# USB0_VBP2APB_WRAP_CONTROLLER_VBP_CORE_ADDR_MAP register map
Vendor: Texas Instruments
Registers are 32-bit, access per field, reset 0x0 unless marked. A register's access mark holds for its fields unless they carry their own. Offsets are as the file gives them; [hi:lo] are bit positions.

## USB0_VBP2APB_WRAP_CONTROLLER_VBP_CORE_ADDR_MAP (part 6 of 9)
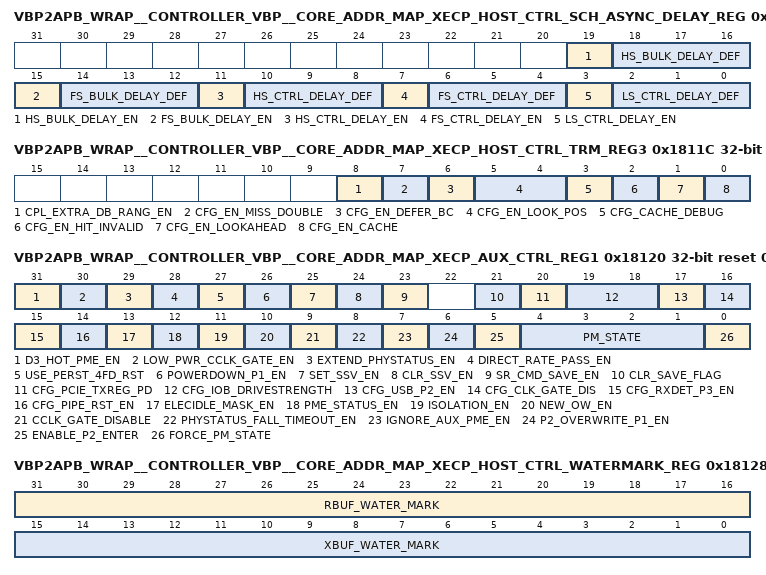
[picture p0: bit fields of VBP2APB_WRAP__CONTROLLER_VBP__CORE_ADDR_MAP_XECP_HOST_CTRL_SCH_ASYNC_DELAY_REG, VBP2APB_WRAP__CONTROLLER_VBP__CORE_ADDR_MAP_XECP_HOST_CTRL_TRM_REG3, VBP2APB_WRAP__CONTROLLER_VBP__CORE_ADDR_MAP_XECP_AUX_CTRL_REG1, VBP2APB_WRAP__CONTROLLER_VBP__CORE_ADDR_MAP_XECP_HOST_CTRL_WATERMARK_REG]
0x18114 VBP2APB_WRAP__CONTROLLER_VBP__CORE_ADDR_MAP_XECP_HOST_CTRL_SCH_ASYNC_DELAY_REG — Scheduler Async Delay. Global defaults for inserting delays between packets in the scheduler for asynchronous types. This is a vendor defined capability. This register is reserved. This register should not be accessed by software. It is described only for informative purposes.
  [19] HS_BULK_DELAY_EN rw — High-Speed Bulk Delay Enable
  [18:16] HS_BULK_DELAY_DEF rw — High-Speed Bulk Delay Default [0=125us,1=250us,2=500us,3=1ms,]
  [15] FS_BULK_DELAY_EN rw — Full-Speed Bulk Delay Enable
  [14:12] FS_BULK_DELAY_DEF rw — Full-Speed Bulk Delay Default [0=125us,1=250us,2=500us,3=1ms,]
  [11] HS_CTRL_DELAY_EN rw — High-Speed Control Delay Enable
  [10:8] HS_CTRL_DELAY_DEF rw — High-Speed Control Delay Default [0=125us,1=250us,2=500us,3=1ms,]
  [7] FS_CTRL_DELAY_EN rw — Full-Speed Control Delay Enable
  [6:4] FS_CTRL_DELAY_DEF rw — Full-Speed Control Default [0=125us,1=250us,2=500us,3=1ms,]
  [3] LS_CTRL_DELAY_EN rw — Low-Speed Control Delay Enable
  [2:0] LS_CTRL_DELAY_DEF rw — Low-Speed Control Delay Default [0=125us,1=250us,2=500us,3=1ms,]
0x18118 VBP2APB_WRAP__CONTROLLER_VBP__CORE_ADDR_MAP_XECP_UPORTS_PON_RST_REG — AUX Power PHY Reset. This register may be read from or written to at any time, including whilst the CNR field in the USBSTS register is high. Allow a USB PHY reset being issued by software. Writing to this register with bit set to 1 will reset the USB PHY that is connected to the port. This is a vendor defined capability. This register is reserved. This register should not be accessed by software. It is described only for informative purposes.
  [3:0] USB_PHY_PORT_NUM wo — Indicates the port number of the USB PHY
0x1811C VBP2APB_WRAP__CONTROLLER_VBP__CORE_ADDR_MAP_XECP_HOST_CTRL_TRM_REG3 reset 0xE7 — Host Control Transfer Manager (TRM) register. This is a vendor defined capability. This register is reserved. This register should not be accessed by software. It is described only for informative purposes.
  [8] CPL_EXTRA_DB_RANG_EN rw
  [7] CFG_EN_MISS_DOUBLE rw — '0': Do not enable cache control to double fetch on miss. '1': Enable cache control to double fetch on miss.
  [6] CFG_EN_DEFER_BC rw — '0': Disable cache control to defer misses on bulk/control EPs. '1': Enable cache control to defer misses on bulk/control EPs.
  [5:4] CFG_EN_LOOK_POS rw — Enable cache control trigger position lookahead.
  [3] CFG_CACHE_DEBUG rw — cfg_cache_debug. Available when TRB_CACHE_DEBUG_EN is defined
  [2] CFG_EN_HIT_INVALID rw — '0': Disable cache control hit invalid with invalid CS, '1': Enable cache control hit invalid with invalid CS.
  [1] CFG_EN_LOOKAHEAD rw — '0': Disable cache control lookahead, '1': Enable cache control lookahead.
  [0] CFG_EN_CACHE rw — '0': Disable cache control, '1': Enable cache control.
0x18120 VBP2APB_WRAP__CONTROLLER_VBP__CORE_ADDR_MAP_XECP_AUX_CTRL_REG1 access not given reset 0x808C39A0 — AUX Power Management Control 1. This register may be read from or written to at any time, including whilst the CNR field in the USBSTS register is high. This is a vendor defined capability. This register is reserved. This register should not be accessed by software. It is described only for informative purposes.
  [31] D3_HOT_PME_EN rw
  [30] LOW_PWR_CCLK_GATE_EN rw — This bit enables gate-off the core clock when AUX PM control is in low power state. '0': disable this function, '1': enabled to gate off the core clock.
  [29] EXTEND_PHYSTATUS_EN rw — This bit is there for a bug fix where we need to ensure that phystatus did not get lost during the rate change where clock switch logic takes some cycles to complete. such that the PCie's core clock is at half of the PCIe PHY pclk. '0': not extended phystatus, '1': extended phystatus assertion
  [28] DIRECT_RATE_PASS_EN rw — Disable the overwrite function in AUX PM control module for its initiated rate change. '0': allows AUX PM control module to initiate its PCIE rate change when it needs to enable P2 overwrite P1 function. '1': AUX PM control module will not alter the PCIe rate change function .
  [27] USE_PERST_4FD_RST rw — Enable AUX reset module to treat every PERST# as a fundamental reset '0': disabled, '1': enabled. This field should not be modified by software
  [26] POWERDOWN_P1_EN rw — This is a test/control bit. This bit is designed to control the lowest powerdown state of the PCIe that AUX PM module signaled to PIPE is P1. '0': drive as normal operation. '1': always drive to P1 instead of P2
  [25] SET_SSV_EN rw — When set to '1' set the SSV flag.
  [24] CLR_SSV_EN rw — When set to '1' clear the SSV flag
  [23] SR_CMD_SAVE_EN rw — A debug control bit, which is used to enable save'n'restore function. '0': disabled. '1': enabled
  [21] CLR_SAVE_FLAG rw — This bit sets the internal save_restore_enable flag to '0' when written to '1'. Software is expected to clear this bit after it wrote this bit to '1'. This is for test/debug purpose of the save'n'restore function. '0': allows regular save'n'restore function to proceed. '1': clear the internal flag save_restore_enable
  [20] CFG_PCIE_TXREG_PD rw
  [19:18] CFG_IOB_DRIVESTRENGTH rw — Controls the drive strength of the IO buffer. Set default IO Strength to 8ma
  [17] CFG_USB_P2_EN rw
  [16] CFG_CLK_GATE_DIS rw
  [15] CFG_RXDET_P3_EN rw — Cfg_rxdet_p3_en. Enable rxdet U3 mode
  [14] CFG_PIPE_RST_EN rw — Cfg_pipe_rst_en_sync.
  [13] ELECIDLE_MASK_EN rw — This bit enables the AUX PM control state machine to take over txelecidle signal of the PIPE during several special conditions. '0': Disable the mask. '1': Allow mask to mac_phy_txeleidle of PCIe core.
  [12] PME_STATUS_EN rw — This bit enables the PCIe status function. '0': xHC as a PCIe device will not generate any PME nor report PME status. '1': xHC as a PCIe device will generate the PME message.
  [11] ISOLATION_EN rw — When set to '1' enable isolation function for dual power zone. This field should not be modified by software
  [10] NEW_OW_EN rw — This bit allows the AUX PM control module to decide whether we entered into P2 overwrite condition based on the power down state of the PCIe core is at P1 or the LTSSM of PCIe core is in L1. What we used to have is based on P1 of the PCIe core mac_phy_powerdown signal. This is not correct because LTSSM can be in RX detect to result a P1 of power down state. To preserve our old function, we add this chicken bit. '0': P2Pverwrite function based on PCIe core PIPE mac_phy_powerdown is in P1, '1': P2OverWrite function based on LTSSM in L1 This field should not be modified by software
  [9] CCLK_GATE_DISABLE rw — When set to '1' disable core clock gating based on low power state entered.
  [8] PHYSTATUS_FALL_TIMEOUT_EN rw — When set to '1' enable PHY status timeout function, which is designed to cover the PCIePHY issue that we may have not be able to detect the PHY status toggle. This is a safety feature in case we have gotten into a deadlock during PHY status acknowledgement.
  [7] IGNORE_AUX_PME_EN rw — When set to '1' ignore the aux_pm_en reg from PCIe core to continue the remote wake/clock switching support
  [6] P2_OVERWRITE_P1_EN rw — When set to '1' enable P2 overwrite P1 when PCIe core has indicated the transition from P0 to P1. This is to enable entering the even lower power state.
  [5] ENABLE_P2_ENTER rw — When set to '1' enables the remote wake function by allowing P2 clock/switching and P2 entering
  [4:1] PM_STATE rw — Forced power management state can be set here. States encoding: PM_ACTIVE : 4'h0. REQ_CLK_SWITCH_2AUX : 4'h1. DRIVE_PHY_2P2 : 4'h2. WAIT_4WAKE : 4'h3. WAIT_4PERST_DSRT : 4'h4. RATE_CHANGE_2FAST : 4'h5. REQ_CLK_SWITCH_2PCLK : 4'h6. PM_EXIT : 4'h7. WAIT_4PCLK : 4'h8. DRIVE_PHY_STATUS : 4'h9. PM_IDLE : 4'hA. PWRUP_REQ_CLK_SWITCH_2PCLK : 4'hB. RATE_CHANGE_2SLOW : 4'hC. WAIT_4LTSSM_WAIT_DONE : 4'hD. WAIT_4CLK_GATE : 4'hE. IN_P2_TIMEOUT : 4'hF. Those bits have also another functionality: [1]: always_wake_n_en, [2]: timeout_16ms_en, [3]: always_force_clk_sw_en, ![4]: rc_p2_exit_en
  [0] FORCE_PM_STATE rw — When set to '1' force PM state to go to the state indicated in field pm_state [bits [4:1]]. This bit is the force PM state register, it is a pulse only [read by software will always give '0']
0x18128 VBP2APB_WRAP__CONTROLLER_VBP__CORE_ADDR_MAP_XECP_HOST_CTRL_WATERMARK_REG rw reset 0x800080 — Port Watermark. This is a vendor defined capability. This register is reserved. This register should not be accessed by software. It is described only for informative purposes.
  [31:16] RBUF_WATER_MARK, [15:0] XBUF_WATER_MARK
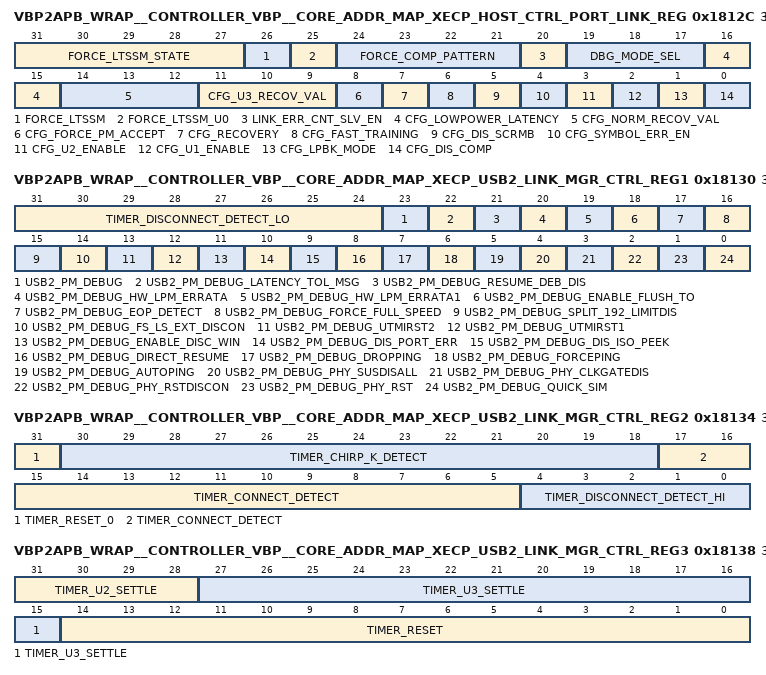
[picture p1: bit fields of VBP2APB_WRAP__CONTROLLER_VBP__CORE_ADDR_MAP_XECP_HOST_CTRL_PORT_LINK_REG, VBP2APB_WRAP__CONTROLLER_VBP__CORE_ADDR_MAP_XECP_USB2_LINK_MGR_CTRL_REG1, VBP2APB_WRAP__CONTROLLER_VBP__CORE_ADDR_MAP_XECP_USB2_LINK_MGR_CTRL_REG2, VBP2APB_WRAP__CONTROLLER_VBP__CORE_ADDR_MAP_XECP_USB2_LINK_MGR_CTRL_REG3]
0x1812C VBP2APB_WRAP__CONTROLLER_VBP__CORE_ADDR_MAP_XECP_HOST_CTRL_PORT_LINK_REG rw reset 0x18030C10 — SuperSpeed Port Link Control. This is a vendor defined capability. This register is reserved. This register should not be accessed by software. It is described only for informative purposes.
  [31:27] FORCE_LTSSM_STATE — LTSSM state to be forced. This value is for test purpose only. Setting bit 4 enables: cfg_relax_rxpolarity_en. Setting bit 3 enables: cfg_relax_linkfunc_en. Setting bit 2 enables: cfg_link_func_en.
  [26] FORCE_LTSSM — '0': Normal operation mode, '1': Direct link to a specific state specified by force_ltssm_state field [bits [31:27]]. This bit is for test purpose only. It shall be written '0' in normal operation mode.
  [25] FORCE_LTSSM_U0 — '0': Normal operation mode, '1': Direct link to U0 This bit is for test purpose only. It shall be written '0' in normal operation mode.
  [24:21] FORCE_COMP_PATTERN — Compliance pattern to be forced to enter compliance mode. This value is for test purpose only.
  [20] LINK_ERR_CNT_SLV_EN
  [19:17] DBG_MODE_SEL — Debug mode select: bit[0]: cfg_port_init_ctrl [if set to '1' tPortConfiguration less than 21us], bit[1]: cfg_relax_ts2_en, bit[2]: cfg_relax_lfps_en.
  [16:15] CFG_LOWPOWER_LATENCY
  [14:12] CFG_NORM_RECOV_VAL — This value defines the minimum time for the link to stay in Recovery. Active other than from U3. The granuity is 128us.
  [11:9] CFG_U3_RECOV_VAL — This value defines the minimum time for the link to stay in Polling.Active and Recovery.Active from U3. The granuity is 128us.
  [8] CFG_FORCE_PM_ACCEPT — '0': Normal operation mode. '1': Force link to accept power management command.
  [7] CFG_RECOVERY — '0': Normal operation mode, '1': Direct link to Recovery from U0.
  [6] CFG_FAST_TRAINING — '0': Normal operation mode, '1': Link fast training mode. This bit should be written '0' in normal operation.
  [5] CFG_DIS_SCRMB — '0': Enable link scrambler, '1': Disable link scrambler.
  [4] CFG_SYMBOL_ERR_EN — '0': Disable detecting RxData error using RxStatus signal, '1': Enable detecting RxData error using RxStatus signal.
  [3] CFG_U2_ENABLE — '0': Normal operation mode, '1': Direct link to U2 from U0. This bit is for test purpose only. It shall be written '0' in normal operation mode.
  [2] CFG_U1_ENABLE — '0': Normal operation mode, '1': Direct link to U1 from U0. This bit is for test purpose only. It shall be written '0' in normal operation mode.
  [1] CFG_LPBK_MODE — '0': Disable link loopback master mode, '1': Enable link loopback master mode.
  [0] CFG_DIS_COMP — '0': Enable link compliance mode, '1': Disable link compliance mode.
0x18130 VBP2APB_WRAP__CONTROLLER_VBP__CORE_ADDR_MAP_XECP_USB2_LINK_MGR_CTRL_REG1 rw reset 0x311803A0 — USB2 Port Link Control 1,2,3,4. This set of registers is used to control the USB set of timers. They are spread over 4 registers each 32 bits wide. This set of registers may be read from or written to at any time, including whilst the CNR field in the USBSTS register is high. This is a vendor defined capability. This register is reserved. This register should not be accessed by software. It is described only for informative purposes.
  [31:24] TIMER_DISCONNECT_DETECT_LO — Number of microseconds of SE0 in FS/LS mode to register disconnect had occurred. First 8 MSB.
  [23] USB2_PM_DEBUG — USB2_PM_DEBUG. usb2_link_mgr_debug register.
  [22] USB2_PM_DEBUG_LATENCY_TOL_MSG — Latency Tolerance Scheme ['0'=when HWLPM is enabled / '1'=when L1 is active].
  [21] USB2_PM_DEBUG_RESUME_DEB_DIS — Clr to eliminate debounce on remote wake detect.
  [20] USB2_PM_DEBUG_HW_LPM_ERRATA — Set to switch the HIRD to BESL format.
  [19] USB2_PM_DEBUG_HW_LPM_ERRATA1 — Set to change the scale of HW LPM timeout to 256us increments.
  [18] USB2_PM_DEBUG_ENABLE_FLUSH_TO — Set to enable flush state timeouts.
  [17] USB2_PM_DEBUG_EOP_DETECT — Set to enable full length SE0 detect.
  [16] USB2_PM_DEBUG_FORCE_FULL_SPEED — Set to reject device chirp and force full-speed
  [15] USB2_PM_DEBUG_SPLIT_192_LIMITDIS — Use to disable 192 byte limit checking on.
  [14] USB2_PM_DEBUG_FS_LS_EXT_DISCON — Use UTMI HostDisconnect input for FS/LS
  [13] USB2_PM_DEBUG_UTMIRST2 — Select UTMI Reset Source 2
  [12] USB2_PM_DEBUG_UTMIRST1 — Select UTMI Reset Source 1
  [11] USB2_PM_DEBUG_ENABLE_DISC_WIN — Enable HS disconnect Window.
  [10] USB2_PM_DEBUG_DIS_PORT_ERR — Enable Remote Wake Resume Trap.
  [9] USB2_PM_DEBUG_DIS_ISO_PEEK — Disable waiting for last indication for USB2 ISO.
  [8] USB2_PM_DEBUG_DIRECT_RESUME — Use FS/LS serial I/F to drive resume.
  [7] USB2_PM_DEBUG_DROPPING — If new ping on endpoint that already had PING, drop the PING.
  [6] USB2_PM_DEBUG_FORCEPING — If retry on endpoint that should have PING, force the PING.
  [5] USB2_PM_DEBUG_AUTOPING — After NYET and new packet coming to same EP - ping N times before give up and flush.
  [4] USB2_PM_DEBUG_PHY_SUSDISALL — Disable PHY suspend for all states.
  [3] USB2_PM_DEBUG_PHY_CLKGATEDIS — Disable PHY suspend during disconnect.
  [2] USB2_PM_DEBUG_PHY_RSTDISCON — Disable Clock Gate
  [1] USB2_PM_DEBUG_PHY_RST — Control PHY Reset Directly
  [0] USB2_PM_DEBUG_QUICK_SIM — Short Timer Values For Simulation of USB2.0 parameters. Please refer to Integration Guide section on Debug Features
0x18134 VBP2APB_WRAP__CONTROLLER_VBP__CORE_ADDR_MAP_XECP_USB2_LINK_MGR_CTRL_REG2 rw reset 0x80C40620 — USB2 Port Link Control 1, 2, 3, 4. This set of registers is used to control the USB set of timers. They are spread over 4 registers each 32 bits wide. This set of registers may be read from or written to at any time, including whilst the CNR field in the USBSTS register is high. This is a vendor defined capability. This register is reserved. This register should not be accessed by software. It is described only for informative purposes.
  [31] TIMER_RESET_0 — Number of microseconds for total reset duration
  [30:18] TIMER_CHIRP_K_DETECT — Number of microseconds of Chirp-K to register that a device is chirping
  [17:5] TIMER_CONNECT_DETECT — Number of microseconds of K/J in disconnected state to register connect has occurred. Last 5 LSBs.
  [4:0] TIMER_DISCONNECT_DETECT_HI — Number of microseconds of SE0 in FS/LS mode to register disconnect had occurred. Last 5 LSBs.
0x18138 VBP2APB_WRAP__CONTROLLER_VBP__CORE_ADDR_MAP_XECP_USB2_LINK_MGR_CTRL_REG3 rw reset 0xF865EB6B — USB2 Port Link Control 1, 2, 3, 4. These set of registers is used to control the USB set of timers. They are spread over 4 registers each 32 bits wide. This set of registers may be read from or written to at any time, including whilst the CNR field in the USBSTS register is high. This is a vendor defined capability. This register is reserved. This register should not be accessed by software. It is described only for informative purposes.
  [31:28] TIMER_U2_SETTLE — Number of microseconds after entering U2. linestate changes are ignored as bus settles. First 4 LSB.
  [27:15] TIMER_U3_SETTLE — Number of microseconds after entering U3. linestate changes are ignored as bus settles
  [14:0] TIMER_RESET — Number of microseconds for total reset duration
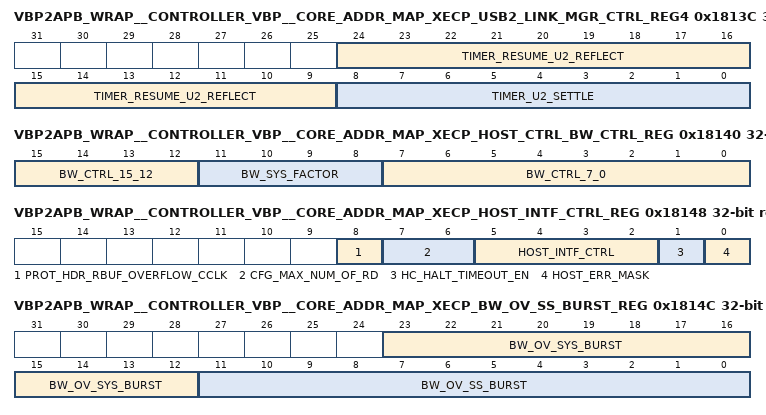
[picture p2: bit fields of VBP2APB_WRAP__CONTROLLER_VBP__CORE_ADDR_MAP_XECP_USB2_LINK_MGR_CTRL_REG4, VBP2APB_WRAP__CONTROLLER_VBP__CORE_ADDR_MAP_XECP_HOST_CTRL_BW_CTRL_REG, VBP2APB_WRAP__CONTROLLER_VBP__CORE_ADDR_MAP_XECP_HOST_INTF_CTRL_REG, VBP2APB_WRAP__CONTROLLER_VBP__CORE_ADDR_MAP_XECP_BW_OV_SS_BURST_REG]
0x1813C VBP2APB_WRAP__CONTROLLER_VBP__CORE_ADDR_MAP_XECP_USB2_LINK_MGR_CTRL_REG4 reset 0x8003 — USB2 Port Link Control 1, 2, 3, 4. These set of registers is used to control the USB set of timers. They are spread over 4 registers each 32 bits wide. This set of registers may be read from or written to at any time, including whilst the CNR field in the USBSTS register is high. This is a vendor defined capability. This register is reserved. This register should not be accessed by software. It is described only for informative purposes.
  [24:9] TIMER_RESUME_U2_REFLECT rw — Number of microseconds after detecting U2 remote wake condition to reflect K
  [8:0] TIMER_U2_SETTLE rw — Number of microseconds after entering U2. linestate changes are ignored as bus settles. Last 9 MSB.
0x18140 VBP2APB_WRAP__CONTROLLER_VBP__CORE_ADDR_MAP_XECP_HOST_CTRL_BW_CTRL_REG reset 0x300 — USB2 Max Bandwidth Control. This register is reserved. This register should not be accessed by software. It is described only for informative purposes.
  [15:12] BW_CTRL_15_12 rw — Max. Percentage BW allowed for SS [default: 80]
  [11:8] BW_SYS_FACTOR rw — System factor for Bandwidth calculation
  [7:0] BW_CTRL_7_0 rw — Miscellaneous Bandwidth calculator configuration bits
0x18144 VBP2APB_WRAP__CONTROLLER_VBP__CORE_ADDR_MAP_XECP_FPGA_REVISION_REG ro reset 0x12000000 — FPGA_REVISION_REG. This is a vendor defined capability. This register is reserved. This register should not be accessed by software. It is described only for informative purposes.
  [31:0] FPGA_REVISION_REG_DEFAULT
0x18148 VBP2APB_WRAP__CONTROLLER_VBP__CORE_ADDR_MAP_XECP_HOST_INTF_CTRL_REG reset 0x1 — Host interface control register. This is a vendor defined capability. This register is reserved. This register should not be accessed by software. It is described only for informative purposes. This field should not be modified by software
  [8] PROT_HDR_RBUF_OVERFLOW_CCLK ro
  [7:6] CFG_MAX_NUM_OF_RD rw — cfg_max_num_of_rd. This is to control how many max number of read that we allow ODMA read to issue. '00': can issue 16 reads '10': can issue 8 reads '01': can issue 4 reads
  [5:2] HOST_INTF_CTRL rw
  [1] HC_HALT_TIMEOUT_EN rw — hc_halt_timeout_en. An internal register bit used to control whether or not to use the hc halt status timer of 15ms
  [0] HOST_ERR_MASK rw — host_err_mask. If set to '1' do not mask the host system error
0x1814C VBP2APB_WRAP__CONTROLLER_VBP__CORE_ADDR_MAP_XECP_BW_OV_SS_BURST_REG reset 0x8020 — BW_OV_SS_BURST_REG. This is a vendor defined capability. This register is reserved. This register should not be accessed by software. It is described only for informative purposes. This field should not be modified by software
  [23:12] BW_OV_SYS_BURST rw, [11:0] BW_OV_SS_BURST rw
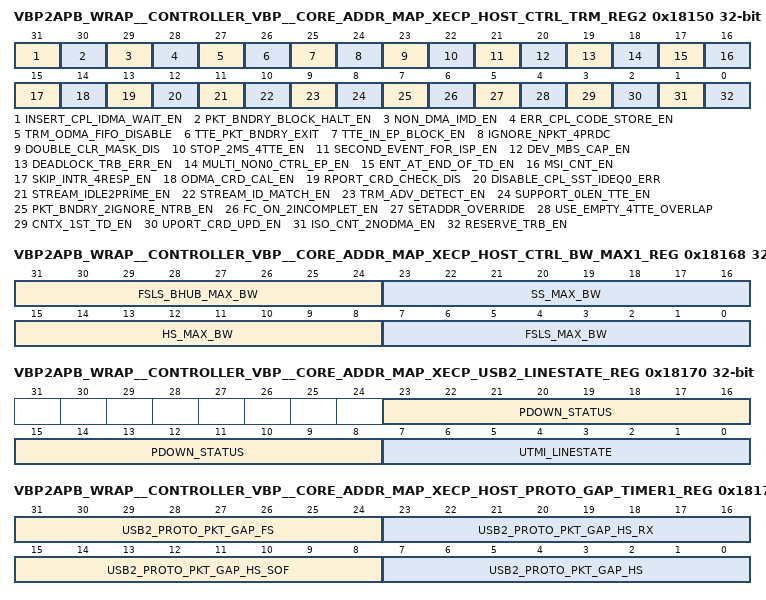
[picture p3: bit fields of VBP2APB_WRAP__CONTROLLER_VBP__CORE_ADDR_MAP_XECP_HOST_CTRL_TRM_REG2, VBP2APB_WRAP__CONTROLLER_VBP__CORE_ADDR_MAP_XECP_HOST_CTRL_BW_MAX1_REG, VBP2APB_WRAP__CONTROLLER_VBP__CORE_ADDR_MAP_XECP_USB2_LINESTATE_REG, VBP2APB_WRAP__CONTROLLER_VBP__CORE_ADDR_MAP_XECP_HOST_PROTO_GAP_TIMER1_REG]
0x18150 VBP2APB_WRAP__CONTROLLER_VBP__CORE_ADDR_MAP_XECP_HOST_CTRL_TRM_REG2 rw reset 0xF0FD838C — Host Control Transfer Manager (TRM) register. This register contains fields, which control the behavior of the Transfer Manager in the xHCI. The functions controlled by this register are made available largely for debug/diagnostic purposes. This functionality is above and beyond that defined in the xHCI specification. This is a vendor defined capability. This register is reserved. This register should not be accessed by software. It is described only for informative purposes.
  [31] INSERT_CPL_IDMA_WAIT_EN — This bit is added for bug FR2601. It is for cache invalidate case where xHC engine needs to insert wait states for completion engine when the completion has received a short packet before XFER engine has finished the TRB fetch for this packet at its packet boundary. '0': Disables the feature, '1': Enables the feature
  [30] PKT_BNDRY_BLOCK_HALT_EN — This bit is added for bug FR2642. It is to delay the completion engine to generate an event due to internal error conditions that halted an EP until XFER engine has reached a packet boundary. '0': Disabled '1': Enabled
  [29] NON_DMA_IMD_EN — This bit is added for bug FR2639. It enables the internal functions where xHC engine needs to immediately serve the EP again. '0': disabled '1': enabled
  [28] ERR_CPL_CODE_STORE_EN — This bit is added for bug FR2495. It enables that error completion code of the first error condition detected within an TD. so that we can report the same error completion codes for all other TRBs within this TD. '0': disabled '1': enables the feature
  [27] TRM_ODMA_FIFO_DISABLE — This bit disables a new feature where xHC engine will have an ODMA FIFO added for the commands between TRM and ODMA. so that we can avoid the back-pressure situation due to the number of outstanding PCIe read limitation. This is for performance enhancement. '0': Enables this feature, '1': Disables this feature.
  [26] TTE_PKT_BNDRY_EXIT — This bit is added for bug FR2446. It is to enable TRM to only send one IN request for TTE 1st phase request even if it has not reached the packet boundary. '0': Disabled, '1': Enabled
  [25] TTE_IN_EP_BLOCK_EN — This bit is added for bug FR2395. It disables the single IN EP for TTE function. '0': Disabled, '1': Allow only single IN EP per port for TTE.
  [24] IGNORE_NPKT_4PRDC — This bit is added for bug FR2333 where the xHC engine has always ignored the credit returned from device for its OUT EP buffers when the EP is a periodic EP. '0': Enable the xHC engine to follow the flow control, '1': Disable this feature.
  [23] DOUBLE_CLR_MASK_DIS — This bit is added for bug FR2283. This is to ensure only one clear pulse generated when a completion has received [disable CPL engine from sending multiple clear]. '0': Disabled, '1': Enabled.
  [22] STOP_2MS_4TTE_EN — This bit enables a 2ms timeout for all TTE related EP stop endpoint command. The xHC engine will not check whether there is a pending response in context. It will only wait for 2ms and indicates that EP has been stopped. '0': Disabled, '1': Enabled.
  [21] SECOND_EVENT_FOR_ISP_EN — This bit enables xHC engine TRM to report the second or more events on an ISP flush on a second or more TRBs with ISP bit set that are flushed for a short packet response received. '0': Disables this feature, '1': Enables this feature.
  [20] DEV_MBS_CAP_EN — This bit enables a new feature where the completion engine of TRM can check the credit returned from remote device to not excceed its max burst size. If it does, we will keep the internal credits in the context to the max burst size so that xHC engine will not transmit more than max burst size. Note: CB has this bit default set to '0'. PPT B0 and LPT will have this bit set to'1'. '0': Disables this feature, '1': Enables this feature.
  [19] DEADLOCK_TRB_ERR_EN — This bit enables an internally detected deadlock situation being treated as an TRB_ERR when reports the event. This is an internal debug function. '0': Disables this feature, '1': Enables this feature.
  [18] MULTI_NON0_CTRL_EP_EN — This bit enables the xHC engine to fully support the non-0 control EP. This bit allows the xHC TRM to keep track of on non-0 control EP per port so that the responses can be routed to the correct DMA engine. '0': Disables this feature, '1': Enables this feature.
  [17] ENT_AT_END_OF_TD_EN — This bit enables xHC engine to evaluate the next TRB even if the EP is at the end of a TD. '0': Disables this feature, '1': Enables this feature.
  [16] MSI_CNT_EN — This bit enables the new Missing service interval detection mechanism. xHC engine will count how many service interval that it missed, and skip over that many TDs. '0': Disables this feature, '1': Enables this feature.
  [15] SKIP_INTR_4RESP_EN — This bit enables a feature where xHC engine will skip a service interval when an Interrupt EP has missed its service interval. '0': Disables this feature, '1': Enables to skip a service interval.
  [14] ODMA_CRD_CAL_EN — New feature added to prevent the back-pressure from ODMA due to the fact that it ran out of ODMA timeout timer resources. This is for performance enhancement. We have put into the ODMA credit is part of resource calculation before TRM allows the next scheduling for OUT EP. '0': Disables this feature, '1': Enables this feature.
  [13] RPORT_CRD_CHECK_DIS — The xHC engine has a feature that can check with Receive Port Credit per root port to whether or not allow the next schedule onto this port [disable the RPORT credit check for IDMA]. This is for performance enhancement. '0': Enables this feature, '1': Disables this feature.
  [12] DISABLE_CPL_SST_IDEQ0_ERR — '0': Report received stream ID of 0x0000 as an error. '1': Disable the error reporting for a received stream ID value of 0x0000. Note: only used when an endpoint is configured for stream operation.
  [11] STREAM_IDLE2PRIME_EN — Enable the host to transfer to the prime-pipe state [and transmit a prime pipe] on each transfer back to the IDLE state. '0': Feature disabled, '1': Feature enabled. Note: Used only when an endpoint is configured for stream operation.
  [10] STREAM_ID_MATCH_EN
  [9] TRM_ADV_DETECT_EN — '0': Disable this function in XFER engine. '1': Enable the XFER engine to auto detecting a missing service interval function when there is a long delay such that we missed a service interval due to the pending response. Note: Only value of '0' is validated.
  [8] SUPPORT_0LEN_TTE_EN — '0': Disable this function. '1': Enable the function to support 0length TTE second phase request from TTE module.
  [7] PKT_BNDRY_2IGNORE_NTRB_EN — '0': Disable this function. '1': Enable a packet pace function under a special condition. This is an internal feature of XFER engine. It is not expected to be used other than default.
  [6] FC_ON_2INCOMPLET_EN — '0': do not enable this function. '1': assert the sch_req_incomplete signal in XFER engine when a context FC is ON. This is an internal safety feature for XFER engine.
  [5] SETADDR_OVERRIDE — '0': Disable the address device command to query a port credit before it is executed in ODMA engine, '1': Enable the address device command to query a port credit before it is executed in ODMA engine.
  [4] USE_EMPTY_4TTE_OVERLAP — '0': Enable XFER engine to use a no-pending response flag as a way of identifying a TTE overlap condition, '1': Enable XFER engine to use context empty flag not assert as a way of identifying a TTE overlap condition.
  [3] CNTX_1ST_TD_EN — '0': disable the context storage, '1': enable the context storage for a flag to identify a DMA request as the first of TD DMA request.
  [2] UPORT_CRD_UPD_EN — '0': Disable the credit redeem, '1': Enable the credit redeem when a port is in NC state.
  [1] ISO_CNT_2NODMA_EN — '0': Disable this non DMA TRB detect function '1': Enable the function where XFER engine uses the remaining burst count as an indication that the next TRB on the transfer ring for an ISO TD is either link TRB or event data TRB.
  [0] RESERVE_TRB_EN — '0': report TRB ERR for reserved TRB type, '1': enable XFER engine to process a reserved TRB type as a NO-OP TRB.
0x18168 VBP2APB_WRAP__CONTROLLER_VBP__CORE_ADDR_MAP_XECP_HOST_CTRL_BW_MAX1_REG rw reset 0x5647F42 — HOST_CTRL_BW_MAX1_REG. This is a vendor defined capability. This register is reserved. This register should not be accessed by software. It is described only for informative purposes.
  [31:24] FSLS_BHUB_MAX_BW — Max. Percentage BW allowed for FS/LS behind hub [default: 90]
  [23:16] SS_MAX_BW — Max. Percentage BW allowed for SS [default: 80]
  [15:8] HS_MAX_BW — Max. Percentage BW allowed for HS [default: 80]
  [7:0] FSLS_MAX_BW — Max. Percentage BW allowed for FS/LS [default: 90]
0x1816C VBP2APB_WRAP__CONTROLLER_VBP__CORE_ADDR_MAP_XECP_HOST_CTRL_BW_MAX2_REG reset 0xF425285 — HOST_CTRL_BW_MAX2_REG. This is a vendor defined capability. This register is reserved. This register should not be accessed by software. It is described only for informative purposes.
  [27:0] BW_MAX_REG59_32 rw
0x18170 VBP2APB_WRAP__CONTROLLER_VBP__CORE_ADDR_MAP_XECP_USB2_LINESTATE_REG ro — USB2_LINESTATE_REG. This register may be read from or written to at any time, including whilst the CNR field in the USBSTS register is high. This register may be read from or written to at any time, including whilst the CNR field in the USBSTS register is high. This is a vendor defined capability. This register is reserved. This register should not be accessed by software. It is described only for informative purposes.
  [23:8] PDOWN_STATUS, [7:0] UTMI_LINESTATE
0x18174 VBP2APB_WRAP__CONTROLLER_VBP__CORE_ADDR_MAP_XECP_HOST_PROTO_GAP_TIMER1_REG rw reset 0xC05140C — HOST_PROTO_GAP_TIMER1_REG. This is a vendor defined capability. This register is reserved. This register should not be accessed by software. It is described only for informative purposes.
  [31:24] USB2_PROTO_PKT_GAP_FS, [23:16] USB2_PROTO_PKT_GAP_HS_RX, [15:8] USB2_PROTO_PKT_GAP_HS_SOF, [7:0] USB2_PROTO_PKT_GAP_HS
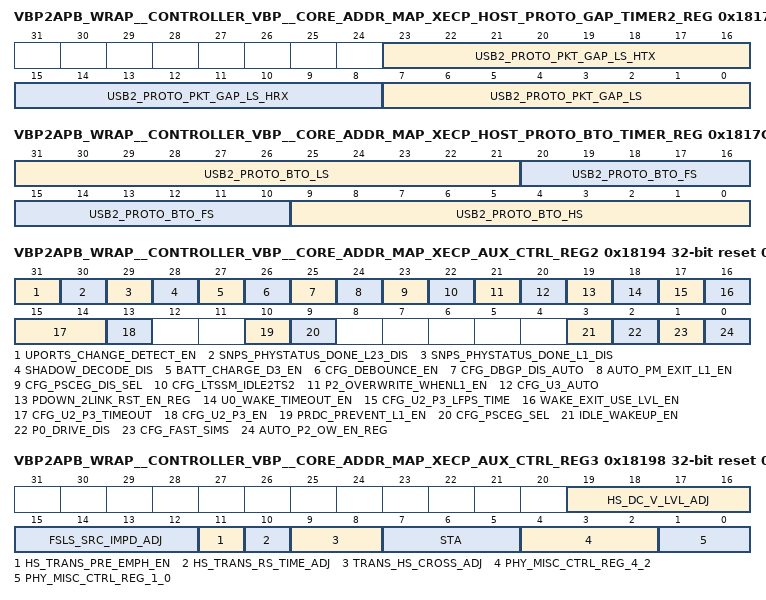
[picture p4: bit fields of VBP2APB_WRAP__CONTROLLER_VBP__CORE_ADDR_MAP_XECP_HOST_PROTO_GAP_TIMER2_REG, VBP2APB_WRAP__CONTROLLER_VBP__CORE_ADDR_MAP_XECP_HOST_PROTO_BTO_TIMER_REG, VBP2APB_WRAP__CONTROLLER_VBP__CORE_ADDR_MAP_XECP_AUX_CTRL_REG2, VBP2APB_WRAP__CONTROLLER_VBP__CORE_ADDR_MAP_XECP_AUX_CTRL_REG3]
0x18178 VBP2APB_WRAP__CONTROLLER_VBP__CORE_ADDR_MAP_XECP_HOST_PROTO_GAP_TIMER2_REG reset 0x2A3C64 — HOST_PROTO_GAP_TIMER2_REG. This is a vendor defined capability. This register is reserved. This register should not be accessed by software. It is described only for informative purposes.
  [23:16] USB2_PROTO_PKT_GAP_LS_HTX rw, [15:8] USB2_PROTO_PKT_GAP_LS_HRX rw, [7:0] USB2_PROTO_PKT_GAP_LS rw
0x1817C VBP2APB_WRAP__CONTROLLER_VBP__CORE_ADDR_MAP_XECP_HOST_PROTO_BTO_TIMER_REG rw reset 0x5B4190B8 — HOST_PROTO_BTO_TIMER_REG. This is a vendor defined capability. This register is reserved. This register should not be accessed by software. It is described only for informative purposes.
  [31:21] USB2_PROTO_BTO_LS, [20:10] USB2_PROTO_BTO_FS, [9:0] USB2_PROTO_BTO_HS
0x18180 VBP2APB_WRAP__CONTROLLER_VBP__CORE_ADDR_MAP_XECP_HOST_CTRL_PSCH_REG rw reset 0xA000000 — HOST_CTRL_PSCH_REG. Specific control register for Power Scheduler. This is a vendor defined capability. This register is reserved. This register should not be accessed by software. It is described only for informative purposes.
  [31:24] PSCH_HOST_CTRL_REG_I_31_24
0x18184 VBP2APB_WRAP__CONTROLLER_VBP__CORE_ADDR_MAP_XECP_HOST_CTRL_PSCH1_REG — HOST_CTRL_PSCH1_REG. Specific internal used control register for Power Scheduler. This is a vendor defined capability. This register is reserved. This register should not be accessed by software. It is described only for informative purposes.
  [11:10] IDLE_SCALE rw — PSCH_HOST_CTRL_REG_I_43_42. idle_scale. 0=1c . 1=1us. 2=125us
0x18190 VBP2APB_WRAP__CONTROLLER_VBP__CORE_ADDR_MAP_XECP_HOST_CTRL_LTM_REG ro — HOST_CTRL_LTM_REG. This is a vendor defined capability. This register is reserved. This register should not be accessed by software. It is described only for informative purposes.
  [11:0] BELT_SELECTED — Reports several of the latencies depending on the last programmed belt_select value: 0: LTV value programmed, 1: Lowest BELT received, 2: Last received LTM per Slot, 3: Last received LTM per Port.
0x18194 VBP2APB_WRAP__CONTROLLER_VBP__CORE_ADDR_MAP_XECP_AUX_CTRL_REG2 rw reset 0xE339060C — AUX Power Management Control 1. This register may be read from or written to at any time, including whilst the CNR field in the USBSTS register is high. This is a vendor defined capability. This register is reserved. This register should not be accessed by software. It is described only for informative purposes.
  [31] UPORTS_CHANGE_DETECT_EN
  [30] SNPS_PHYSTATUS_DONE_L23_DIS
  [29] SNPS_PHYSTATUS_DONE_L1_DIS
  [28] SHADOW_DECODE_DIS
  [27] BATT_CHARGE_D3_EN
  [26] CFG_DEBOUNCE_EN
  [25] CFG_DBGP_DIS_AUTO
  [24] AUTO_PM_EXIT_L1_EN — This bit enables a L1 exit notification to SNPS PCIe core. There is a case where USB ports have waked up and AUX PM module has started the wakeup process. The AUX PM control state got into a wait for P0 state because it needs to wait until PCie core to signal powerdown state change. Due to the fact that the core is in D3Hot, there is no run_stop bit set such that no internal interrupt will be fired. This causes the LTSSM of PCIe stayed in L1 even though AUX PM has known that it needs an L1 exit. This bit works together with bit 21 of this register. '0': Disables this feature. '1': Enables this feature
  [23] CFG_PSCEG_DIS_SEL — '0': Assert PLC for disconnection, '1': Do not assert PLC for disconnection
  [22] CFG_LTSSM_IDLE2TS2 — This bit enables a feature in PCie core LTSSM to treat IDLE received as TS2 when LTSSM is in wait for TS2 receive state. This is a function requested from PHY where it is possible to not able to receive TS2 without error. '0': Disable this feature. '1': Treat Logic IDLE as TS2 received when in some PCIe LTSSM state.
  [21] P2_OVERWRITE_WHENL1_EN — We have added a feature where if PCIe core LTSSM enters L1 due to the D3hot, the aux PM control will not start a P2 overwrite function in anticipating for the next L23 enter. '0': enables P2 overwrite even if we are in D3Hot. '1': disables P2 overwrite due to the D3HOT where PCIe core enters the L1.
  [20] CFG_U3_AUTO — '0': Disables the port to enter U3 automatically when in U1/U2, '1': Enables the port to enter U3 automatically when in U1/U2.
  [19] PDOWN_2LINK_RST_EN_REG — pdown_2link_rst_en
  [18] U0_WAKE_TIMEOUT_EN — This bit enables a feature in AUX PM module where if PCIe core LTSSM is in P0 for a duration of time, we will exit the deep sleep state. This is for failure control in case. '0': disable this feature, '1': enables this feature.
  [17] CFG_U2_P3_LFPS_TIME — This bit selects U2 exit LFPS timer value. '0': 320ns - 400ns in 25MHz domain, '1': 240ns - 320ns in 25MHz domain.
  [16] WAKE_EXIT_USE_LVL_EN — This bit enables a function that AUX PM module exits from the deep sleep state due to the USB ports wakeup level signal. We have added this feature where USB ports will generate a wakeup level signal to wakeup the AUX PM module if it is in deep sleep state and this level signal will be cleared if the change bits are updated by software. '0': Disables this function, which means that a wakeup pulse generated from each USB PortSC event will wake up the AUX PM module from deep sleep if the D3 state is programmed. '1': Enables this function.
  [15:14] CFG_U2_P3_TIMEOUT — This field defines the timeout value to enter P3 mode in U2. 00: 7us - 8us, 01: 511us - 512us, 10: disables the timer [0us], 11: disables the timer [0us].
  [13] CFG_U2_P3_EN — '0': disables PHY P3 mode in U2. '1': enables PHY P3 mode in U2.
  [10] PRDC_PREVENT_L1_EN — This bit enables a function that the SPNS PCIe core is controlled by xHCI engine internal periodic EP traffic conditions. '0': Disabled this function '1': Enables the xHC engine to request an exit of L1 when the service time has reached for an periodic EP.
  [9] CFG_PSCEG_SEL — This bit selects the port status change event generation mode. '0': port status change event is only blocked by the individual status change bit. '1': port status change event is blocked until all status change bit are cleared.
  [3] IDLE_WAKEUP_EN — This bit enables the AUX PM module to automatically wakeup from deep power down when engine has detected non-idle condition. '0': feature disabled '1': feature enabled
  [2] P0_DRIVE_DIS — This bit ensures the P1 drive during PERST#. '0': feature disabled, '1': feature enabled.
  [1] CFG_FAST_SIMS — This bit is for simulation modes only. It enables further reductions to simulation timings in addition to cfg_fast_training. Please refer to Integration Guide Debug Features section '0': Normal timings '1': Enable fast simulation timing modes
  [0] AUTO_P2_OW_EN_REG — This bit enables a feature where we can get P2 overwrite to automatically turned on when there is no pending traffic in the engine. '0': feature disabled, '1': feature enabled. This field should not be modified by software
0x18198 VBP2APB_WRAP__CONTROLLER_VBP__CORE_ADDR_MAP_XECP_AUX_CTRL_REG3 reset 0x83370 — Configuration bits for USB2 PHY. This register may be read from or written to at any time, including whilst the CNR field in the USBSTS register is high. This is a vendor defined capability. This register is reserved. This register should not be accessed by software. It is described only for informative purposes.
  [19:16] HS_DC_V_LVL_ADJ rw — HS DC Voltage Level Adjustment
  [15:12] FSLS_SRC_IMPD_ADJ rw — FS/LS Source Impedance Adjustment
  [11] HS_TRANS_PRE_EMPH_EN rw — HS Transmitter Pre-Emphasis Enable
  [10] HS_TRANS_RS_TIME_ADJ rw — HS Transmitter Rise/Fall Time Adjustment
  [9:8] TRANS_HS_CROSS_ADJ rw — Transmitter High-Speed Crossover Adjustment
  [7:5] STA rw — Squelch Threshold Adjustment
  [4:2] PHY_MISC_CTRL_REG_4_2 rw
  [1:0] PHY_MISC_CTRL_REG_1_0 rw
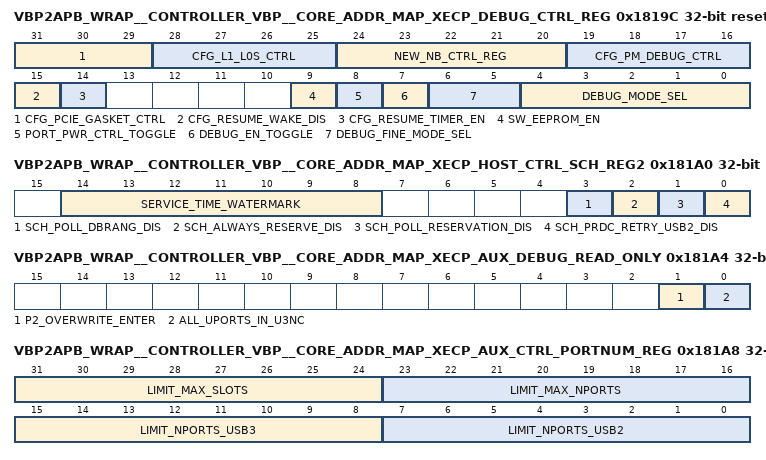
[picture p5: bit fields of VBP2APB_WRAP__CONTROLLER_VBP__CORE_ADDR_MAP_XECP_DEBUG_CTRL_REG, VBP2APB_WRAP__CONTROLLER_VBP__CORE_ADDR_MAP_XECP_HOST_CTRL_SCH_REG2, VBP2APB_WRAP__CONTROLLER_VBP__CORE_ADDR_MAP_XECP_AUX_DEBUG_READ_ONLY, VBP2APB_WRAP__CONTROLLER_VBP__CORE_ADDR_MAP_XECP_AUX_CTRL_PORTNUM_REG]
0x1819C VBP2APB_WRAP__CONTROLLER_VBP__CORE_ADDR_MAP_XECP_DEBUG_CTRL_REG rw reset 0x2000000 — DEBUG_CTRL_REG. This register may be read from or written to at any time, including whilst the CNR field in the USBSTS register is high. This is a vendor defined capability. This register is reserved. This register should not be accessed by software. It is described only for informative purposes.
  [31:29] CFG_PCIE_GASKET_CTRL — cfg_pcie_gasket_ctrl[2:0] This field should not be modified by software
  [28:25] CFG_L1_L0S_CTRL — cfg_l1_l0s_ctrl[3:0] This field should not be modified by software
  [24:20] NEW_NB_CTRL_REG — new_nb_ctrl_reg. Used in aux_pm module to keep old NB behavior. This field should not be modified by software
  [19:16] CFG_PM_DEBUG_CTRL — cfg_pm_debug_ctrl. Used in aux_power_logic.v for debug. This field should not be modified by software
  [15] CFG_RESUME_WAKE_DIS — cfg_resume_wake_dis This field should not be modified by software
  [14] CFG_RESUME_TIMER_EN — cfg_resume_timer_en This field should not be modified by software
  [9] SW_EEPROM_EN — debug control for CoosBay: sw_eeprom_en This field should not be modified by software
  [8] PORT_PWR_CTRL_TOGGLE — debug control for CoosBay: port_pwr_ctrl_toggle This field should not be modified by software
  [7] DEBUG_EN_TOGGLE — debug control for CoosBay: debug_en_toggle This field should not be modified by software
  [6:5] DEBUG_FINE_MODE_SEL — debug_fine_mode_sel This field should not be modified by software
  [4:0] DEBUG_MODE_SEL — debug_mode_sel This field should not be modified by software
0x181A0 VBP2APB_WRAP__CONTROLLER_VBP__CORE_ADDR_MAP_XECP_HOST_CTRL_SCH_REG2 reset 0x7A00 — Host Control Scheduler. This is a vendor defined capability. This register is reserved. This register should not be accessed by software. It is described only for informative purposes.
  [14:8] SERVICE_TIME_WATERMARK rw
  [3] SCH_POLL_DBRANG_DIS rw — Host Control Scheduler: sch_poll_dbrang_dis
  [2] SCH_ALWAYS_RESERVE_DIS rw — Host Control Scheduler: sch_always_reserve_dis
  [1] SCH_POLL_RESERVATION_DIS rw — Host Control Scheduler: sch_poll_reservation_dis
  [0] SCH_PRDC_RETRY_USB2_DIS rw — Host Control Scheduler: sch_prdc_retry_usb2_dis
0x181A4 VBP2APB_WRAP__CONTROLLER_VBP__CORE_ADDR_MAP_XECP_AUX_DEBUG_READ_ONLY ro reset 0x1 — AUX_DEBUG_READ_ONLY. This register may be read from or written to at any time, including whilst the CNR field in the USBSTS register is high. This is a vendor defined capability. This register is reserved. This register should not be accessed by software. It is described only for informative purposes.
  [1] P2_OVERWRITE_ENTER — p2_overwrite_enter, sticky bit
  [0] ALL_UPORTS_IN_U3NC — all_uports_in_u3nc. If set all ports are in U3NC state.
0x181A8 VBP2APB_WRAP__CONTROLLER_VBP__CORE_ADDR_MAP_XECP_AUX_CTRL_PORTNUM_REG ro reset 0x40020101 — AUX_CTRL_PORTNUM_REG. This register may be read from or written to at any time, including whilst the CNR field in the USBSTS register is high. This is a vendor defined capability. This register is reserved. This register should not be accessed by software. It is described only for informative purposes.
  [31:24] LIMIT_MAX_SLOTS — Limit Max slots to fewer then synthesized [strap]
  [23:16] LIMIT_MAX_NPORTS — Limit Max ports to fewer then synthesized [strap]
  [15:8] LIMIT_NPORTS_USB3 — Limit USB3 ports to fewer then synthesized [strap] This field should not be modified by software
  [7:0] LIMIT_NPORTS_USB2 — Limit USB2 ports to fewer then synthesized [strap]
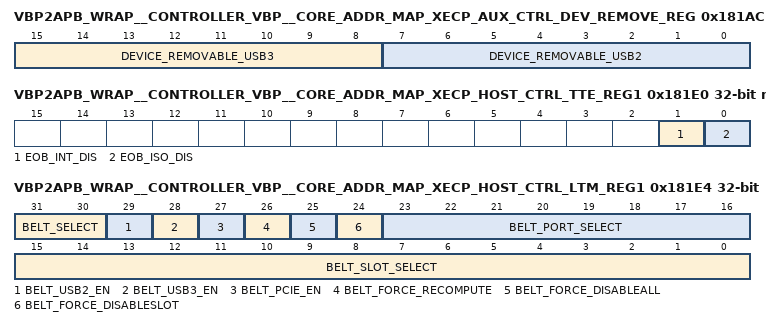
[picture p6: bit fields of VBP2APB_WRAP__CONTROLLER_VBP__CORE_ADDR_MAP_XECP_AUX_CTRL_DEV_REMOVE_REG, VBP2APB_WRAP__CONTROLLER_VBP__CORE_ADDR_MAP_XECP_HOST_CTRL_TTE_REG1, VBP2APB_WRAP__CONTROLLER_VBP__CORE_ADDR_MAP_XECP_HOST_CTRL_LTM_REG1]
0x181AC VBP2APB_WRAP__CONTROLLER_VBP__CORE_ADDR_MAP_XECP_AUX_CTRL_DEV_REMOVE_REG ro — Feature #3002 (Device Removable in PORTSC). This register may be read from or written to at any time, including whilst the CNR field in the USBSTS register is high. This register is reserved. This is a vendor defined capability. This register should not be accessed by software. It is described only for informative purposes.
  [15:8] DEVICE_REMOVABLE_USB3 — Set to 1 if port has non-removable device [strap to 0/1]
  [7:0] DEVICE_REMOVABLE_USB2 — Set to 1 if port has non-removable device [strap to 0/1]
0x181E0 VBP2APB_WRAP__CONTROLLER_VBP__CORE_ADDR_MAP_XECP_HOST_CTRL_TTE_REG1 reset 0x2 — Specific control register for SCH. This is a vendor defined capability. This register is reserved. This register should not be accessed by software. It is described only for informative purposes.
  [1] EOB_INT_DIS rw — Disable end of burst workaround INT [0 length on final MDATA]
  [0] EOB_ISO_DIS rw — Disable end of burst workaround ISO [0 length on final MDATA]
0x181E4 VBP2APB_WRAP__CONTROLLER_VBP__CORE_ADDR_MAP_XECP_HOST_CTRL_LTM_REG1 rw — HOST_CTRL_LTM_REG1. This is a vendor defined capability. This register is reserved. This register should not be accessed by software. It is described only for informative purposes.
  [31:30] BELT_SELECT — Selects which BELT value should be reported on the belt_selected field when the register is read. 0 - LTV value programmed, 1 - Lowest BELT received, 2 - Last received LTM per Slot, 3 - Last received LTM per Port.
  [29] BELT_USB2_EN — belt_usb2_en, active '0', default enabled
  [28] BELT_USB3_EN — belt_usb3_en, active '0', default enabled
  [27] BELT_PCIE_EN — belt_pcie_en, default disabled
  [26] BELT_FORCE_RECOMPUTE
  [25] BELT_FORCE_DISABLEALL
  [24] BELT_FORCE_DISABLESLOT
  [23:16] BELT_PORT_SELECT — Port Number for the BELT reported on the belt_selected field when belt_select is 3
  [15:0] BELT_SLOT_SELECT — Slot-ID for BELT reported on the belt_selected field when belt_select is 2
